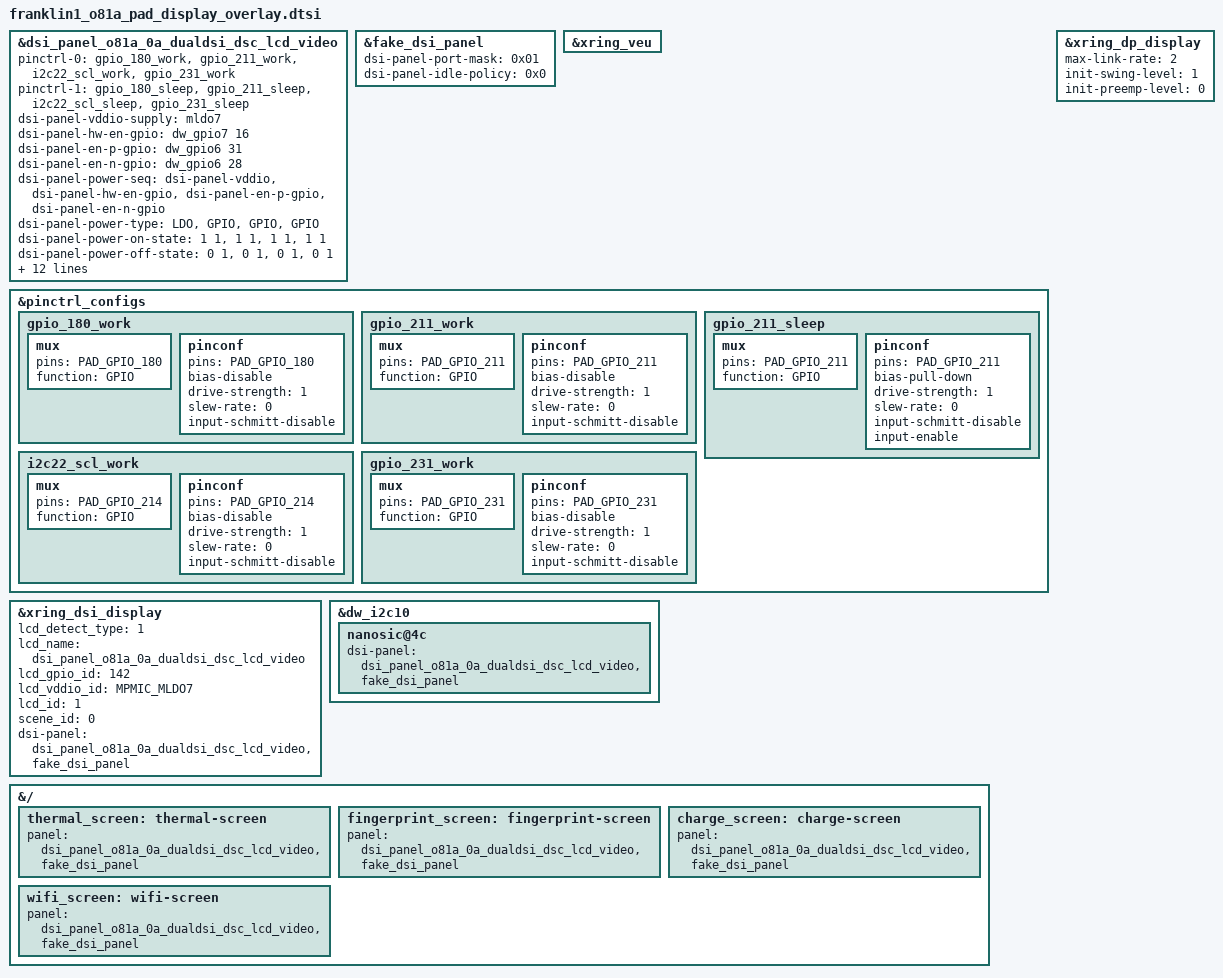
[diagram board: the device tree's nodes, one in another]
// SPDX-License-Identifier: GPL-2.0+
/*
 * Display subsystem overlay dts for X-Ring Franklin
 *
 * (C) Copyright 2023 - 2023, X-Ring, Inc.
 */
#include "../../../../panel/fake_dsi_panel.dtsi"
#include "../../../../panel/dsi_panel_o81a_36_02_0a_dualdsi_dsc_lcd_video.dtsi"
#include <dt-bindings/xring/platform-specific/pmic/pmic_regulator_def.h>

&dsi_panel_o81a_0a_dualdsi_dsc_lcd_video {
	status = "okay";

	pinctrl-names = "work", "sleep";
	pinctrl-0 = <&gpio_180_work &gpio_211_work &i2c22_scl_work &gpio_231_work>;
	pinctrl-1 = <&gpio_180_sleep &gpio_211_sleep &i2c22_scl_sleep &gpio_231_sleep>;

	/* used in kernel
	 * dsi-panel-power-seq: the sequence of the power on IO property name
	 * dsi-panel-power-type: the power supply type
	 * dsi-panel-power-on-state: the power on state sequeue pair <level delay>
	 * level:   0-pull down  1-pull up
	 * delay:   the delay(ms) after IO operation
	 */
	dsi-panel-vddio-supply = <&mldo7>;
	dsi-panel-hw-en-gpio = <&dw_gpio7 16 0>; // 231
	dsi-panel-en-p-gpio = <&dw_gpio6 31 0>; // 214
	dsi-panel-en-n-gpio = <&dw_gpio6 28 0>; // 211

	dsi-panel-power-seq = "dsi-panel-vddio",
			      "dsi-panel-hw-en-gpio",
			      "dsi-panel-en-p-gpio",
			      "dsi-panel-en-n-gpio";
	dsi-panel-power-type = "LDO", "GPIO", "GPIO", "GPIO";
	dsi-panel-power-on-state = <1 1>, <1 1>, <1 1>, <1 1>;
	dsi-panel-power-off-state = <0 1>, <0 1>, <0 1>, <0 1>;

	dsi-panel-reset-gpio = <&dw_gpio5 29 0>; // 180
	dsi-panel-reset-state = <1 1>, <0 3>, <1 10>;

	//dsi-panel-esd-err-irq-gpio-0 = <&dw_gpio0 11 0x2004>; // 11
	/* IRQF_ONESHOT | IRQF_TRIGGER_HIGH */
	//dsi-panel-erd-err-irq-gpio-0-flag = <0x2004>;
	//dsi-panel-esd-err-irq-gpio-1 = <&dw_gpio2 3 0x2004>; // 67
	/* IRQF_ONESHOT | IRQF_TRIGGER_HIGH */
	//dsi-panel-esd-err-irq-gpio-1-flag = <0x2004>;

	/* used in uefi
	 * Sequence Pattern: io_type io_id seq_num level_0 delay_0 [level_1 delay_1 ...]
	 * io_type: 0-INVALID 1-GPIO 2-LDO
	 * seq_num: number of sequeue pair{level delay}
	 * level:   0-pull down  1-pull up
	 * delay:   the delay(ms) after IO operation
	 */
	dsi-panel-power-on-seq =  <2 MPMIC_MLDO7 1 1 2>, /* vddio */
				  <1 231 1 1 1>, /* i2c hw_en */
				  <1 214 1 1 1>, /* i2c en_p */
				  <1 211 1 1 1>; /* i2c en_n */

	dsi-panel-reset-on-seq = <1 180 3 1 1 0 3 1 10>; /* reset */

	dsi-panel-power-off-seq = <1 211 1 0 1>, /* i2c en_n */
				  <1 214 1 0 1>, /* i2c en_p */
				  <1 231 1 0 1>, /* i2c hw_en */
				  <2 MPMIC_MLDO7 1 0 2>; /* vddio */

	dsi-panel-reset-off-seq = <1 180 1 0 2>; /* reset */

	dsi-panel-port-mask = /bits/ 8 <0x3>; // 0011
	dsi-panel-idle-policy = <0x2002>;
	dsi-panel-te-gpio-num = <141>; // 141
};

&fake_dsi_panel {
	status = "okay";
	dsi-panel-port-mask = /bits/ 8 <0x01>; // 0001
	dsi-panel-idle-policy = <0x0>;
};

&xring_veu {
	status = "okay";
};

&pinctrl_configs {
	gpio_180_work: gpio_180_work {
		mux {
			pins = "PAD_GPIO_180";
			function = "GPIO";
		};
		pinconf {
			pins = "PAD_GPIO_180";
			bias-disable;
			drive-strength= <1>;
			slew-rate= <0>;
			input-schmitt-disable;
		};
	};
	gpio_211_work: gpio_211_work {
		mux {
			pins = "PAD_GPIO_211";
			function = "GPIO";
		};
		pinconf {
			pins = "PAD_GPIO_211";
			bias-disable;
			drive-strength= <1>;
			slew-rate= <0>;
			input-schmitt-disable;
		};
	};
	gpio_211_sleep: gpio_211_sleep {
		mux {
			pins = "PAD_GPIO_211";
			function = "GPIO";
		};
		pinconf {
			pins = "PAD_GPIO_211";
			bias-pull-down;
			drive-strength= <1>;
			slew-rate= <0>;
			input-schmitt-disable;
			input-enable;
		};
	};
	i2c22_scl_work: i2c22_scl_work {
		mux {
			pins = "PAD_GPIO_214";
			function = "GPIO";
		};
		pinconf {
			pins = "PAD_GPIO_214";
			bias-disable;
			drive-strength= <1>;
			slew-rate= <0>;
			input-schmitt-disable;
		};
	};
	gpio_231_work: gpio_231_work {
		mux {
			pins = "PAD_GPIO_231";
			function = "GPIO";
		};
		pinconf {
			pins = "PAD_GPIO_231";
			bias-disable;
			drive-strength= <1>;
			slew-rate= <0>;
			input-schmitt-disable;
		};
	};
};

&xring_dsi_display {
	/*
	 * The `lcd_detect_type` property has three options:
	 * 0: Detect by lcd_name
	 * 1: Detect by lcd_gpio_id
	 * 2: Detect by lcd_build_id
	 */
	lcd_detect_type = <1>;
	lcd_name = "dsi_panel_o81a_0a_dualdsi_dsc_lcd_video";
	/* select lcd_name according to build id
	 * build_id: the array of product build id
	 * build_id_name string array of panel dts node name
	 */
	/*build_id = <0x00 0x10 0x40 0x50 0x80 0x90 0xC0>;
	build_id_name = "dsi_panel_o81a_0a_dualdsi_dsc_lcd_video",//p00
			"dsi_panel_o81a_0a_dualdsi_dsc_lcd_video",//p01
			"dsi_panel_o81a_0a_dualdsi_dsc_lcd_video",//p10
			"dsi_panel_o81a_0a_dualdsi_dsc_lcd_video",//p11
			"dsi_panel_o81a_0a_dualdsi_dsc_lcd_video",//p20
			"dsi_panel_o81a_0a_dualdsi_dsc_lcd_video",//p21
			"dsi_panel_o81a_0a_dualdsi_dsc_lcd_video";//MP*/

	lcd_gpio_id = <142>;
	lcd_vddio_id = <MPMIC_MLDO7>;
	lcd_id = <1>;

	scene_id = <0>;

	dsi-panel = <&dsi_panel_o81a_0a_dualdsi_dsc_lcd_video>,
				<&fake_dsi_panel>;
};

&dw_i2c10 {
    nanosic@4c {
	dsi-panel = <&dsi_panel_o81a_0a_dualdsi_dsc_lcd_video>,
				<&fake_dsi_panel>;
    };
};

&{/} {
	thermal_screen: thermal-screen {
		panel = <&dsi_panel_o81a_0a_dualdsi_dsc_lcd_video>,
				<&fake_dsi_panel>;
	};

	fingerprint_screen: fingerprint-screen {
		panel = <&dsi_panel_o81a_0a_dualdsi_dsc_lcd_video>,
				<&fake_dsi_panel>;
	};

	charge_screen: charge-screen {
		panel = <&dsi_panel_o81a_0a_dualdsi_dsc_lcd_video>,
				<&fake_dsi_panel>;
	};

	wifi_screen: wifi-screen {
		panel = <&dsi_panel_o81a_0a_dualdsi_dsc_lcd_video>,
				<&fake_dsi_panel>;
	};
};

&xring_dp_display {
    max-link-rate = <2>; //5.4G
    init-swing-level = <1>;
    init-preemp-level = <0>;
};
